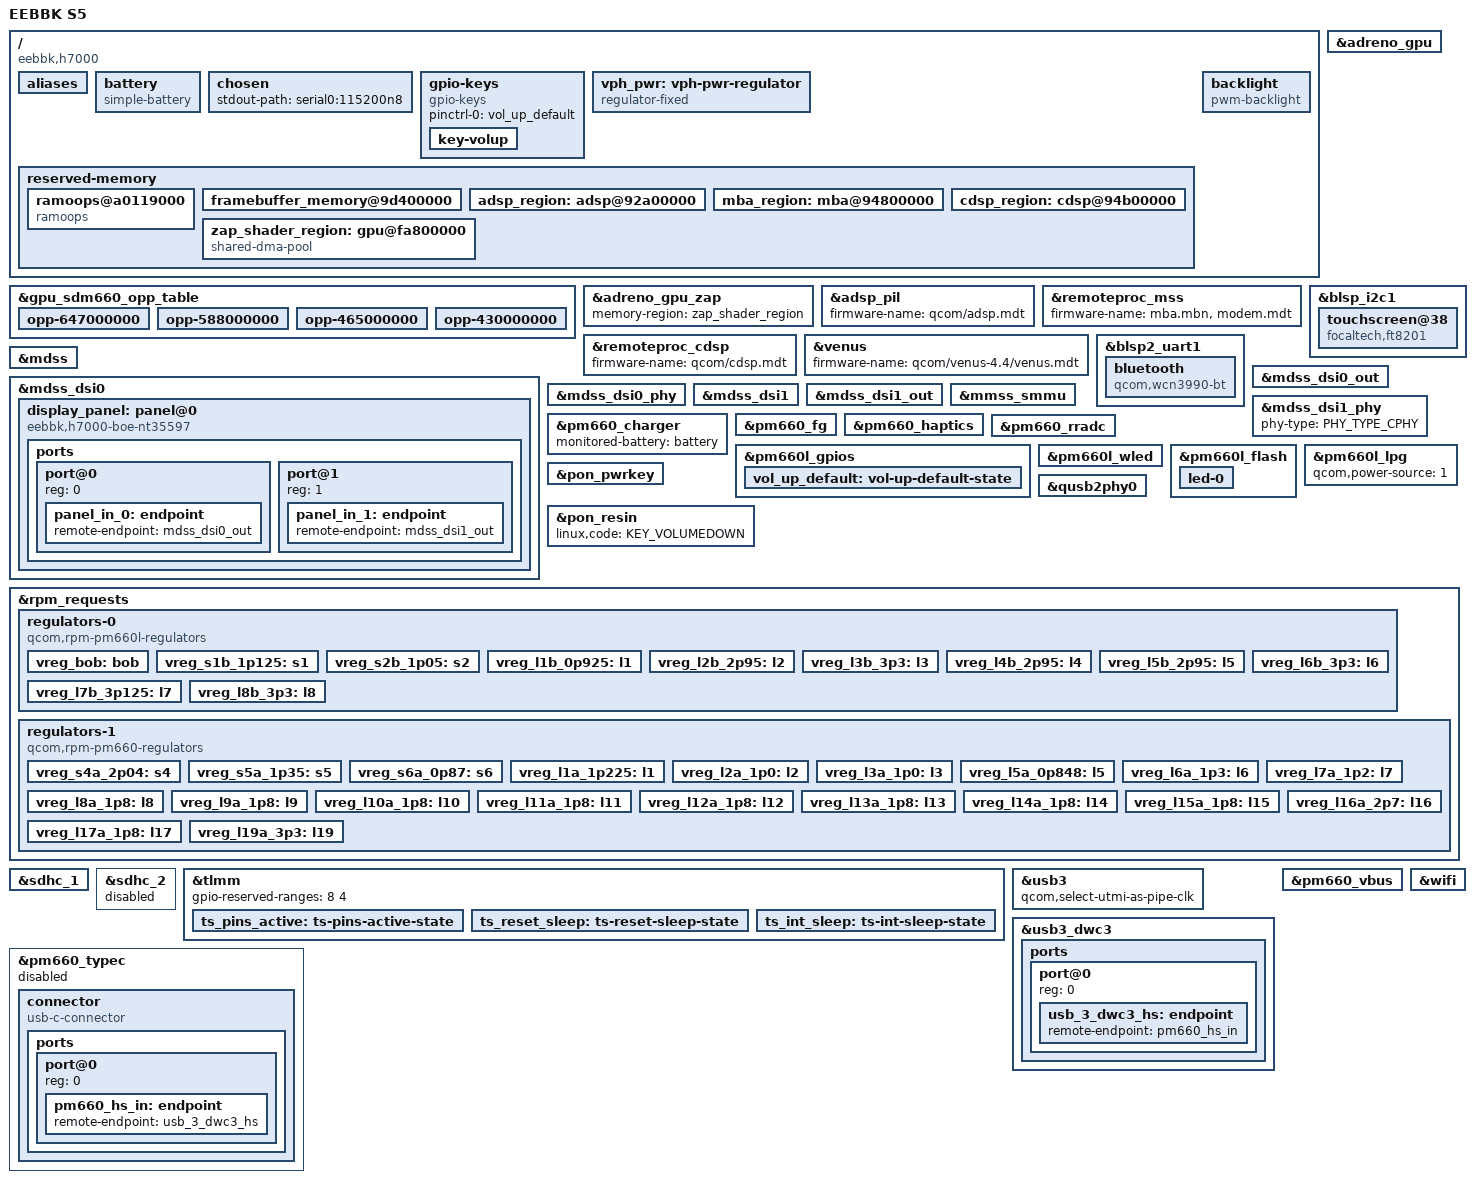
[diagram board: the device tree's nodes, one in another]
// SPDX-License-Identifier: BSD-3-Clause
/*
* Copyright (c) 2025-2026, XiKoTaSu <3329989998@qq.com>
* Copyright (c) 2026, thka <thka2020@qq.com>
*/

/dts-v1/;

#include "sdm660.dtsi"
#include "pm660.dtsi"
#include "pm660l.dtsi"
#include <dt-bindings/gpio/gpio.h>
#include <dt-bindings/input/input.h>
#include <dt-bindings/input/gpio-keys.h>
#include <dt-bindings/leds/common.h>
#include <dt-bindings/pinctrl/qcom,pmic-gpio.h>
#include <dt-bindings/sound/qcom,q6afe.h>
#include <dt-bindings/sound/qcom,q6asm.h>
#include <dt-bindings/phy/phy.h>

/delete-node/ &adsp_region;
/delete-node/ &cdsp_region;
/delete-node/ &mba_region;
/delete-node/ &zap_shader_region;

/ {
	model = "EEBBK S5";
	compatible = "eebbk,h7000", "qcom,sda660";
	chassis-type = "tablet";

	aliases {
		serial0 = &blsp1_uart2; /* Debug UART */
		serial1 = &blsp2_uart1; /* Bluetooth UART */
	};

	battery: battery {
		compatible = "simple-battery";

		charge-full-design-microamp-hours = <6665000>;
		voltage-min-design-microvolt = <3400000>;
		voltage-max-design-microvolt = <4408000>;
	};

	chosen {
		#address-cells = <2>;
		#size-cells = <2>;
		ranges;

		stdout-path = "serial0:115200n8";

		// framebuffer0: framebuffer@9d400000 {
		// 	compatible = "simple-framebuffer";
		// 	reg = <0 0x9d400000 0x0 0x2400000>;
		// 	width = <1600>;
		// 	height = <2176>;
		// 	stride = <(1600 * 4)>;
		// 	format = "a8r8g8b8";
		// };
	};

	gpio-keys {
		compatible = "gpio-keys";

		pinctrl-0 = <&vol_up_default>;
		pinctrl-names = "default";

		key-volup {
			label = "Volume Up";
			gpios = <&pm660l_gpios 7 GPIO_ACTIVE_LOW>;
			linux,code = <KEY_VOLUMEUP>;
			debounce-interval = <15>;
		};
	};

	vph_pwr: vph-pwr-regulator {
		compatible = "regulator-fixed";
		regulator-name = "vph_pwr";
		regulator-min-microvolt = <3700000>;
		regulator-max-microvolt = <3700000>;

		regulator-always-on;
		regulator-boot-on;
	};

	reserved-memory {
		#address-cells = <2>;
		#size-cells = <2>;
		ranges;

		ramoops@a0119000 {
			compatible = "ramoops";
			reg = <0x0 0xa0119000 0x0 0xe0000>;
			console-size = <0x10000>;
			record-size = <0x1000>;
			ftrace-size = <0x1000>;
			pmsg-size = <0x10000>;
		};

		framebuffer_memory@9d400000 {
			reg = <0x0 0x9d400000 0x0 0x2400000>;
			no-map;
		};
		
		adsp_region: adsp@92a00000 {
			reg = <0x0 0x92a00000 0x0 0x1e00000>;
			no-map;
		};

		mba_region: mba@94800000 {
			reg = <0x0 0x94800000 0x0 0x200000>;
			no-map;
		};

		cdsp_region: cdsp@94b00000 {
			reg = <0x00 0x94b00000 0x00 0x600000>;
			no-map;
		};
		
		zap_shader_region: gpu@fa800000 {
			compatible = "shared-dma-pool";
			reg = <0x0 0xfe700000 0x0 0x2000>;
			no-map;
		};
	};

	backlight: backlight {
		compatible = "pwm-backlight";
		pwms = <&pm660l_lpg 3 65536>;

		brightness-levels = <0 255>;
		num-interpolated-steps = <255>;
		default-brightness-level = <100>;
	};

};

&gpu_sdm660_opp_table {
		/* bins 157,146,135 -> bits 6,5,4 */
		opp-647000000 {
			opp-hz = /bits/ 64 <647000000>;
			opp-level = <RPM_SMD_LEVEL_NOM_PLUS>;
			opp-peak-kBps = <4068000>;
			opp-supported-hw = <0xff>;
		};

		/* bins 157,146,135 -> bits 6,5,4 */
		opp-588000000 {
			opp-hz = /bits/ 64 <588000000>;
			opp-level = <RPM_SMD_LEVEL_NOM>;
			opp-peak-kBps = <3072000>;
			opp-supported-hw = <0xff>;
		};

		/* bins 157,146,135,122 -> bits 6,5,4,3 */
		opp-465000000 {
			opp-hz = /bits/ 64 <465000000>;
			opp-level = <RPM_SMD_LEVEL_SVS_PLUS>;
			opp-peak-kBps = <2724000>;
			opp-supported-hw = <0xff>;
		};

		/* this one is for SDM636 with bin 90, bit 2 */
		opp-430000000 {
			opp-hz = /bits/ 64 <430000000>;
			opp-level = <RPM_SMD_LEVEL_SVS_PLUS>;
			opp-peak-kBps = <2724000>;
			opp-supported-hw = <0xff>;
		};
};

&adreno_gpu {
	status = "okay";
};

&adreno_gpu_zap {
	// firmware-name = "a512_zap.mdt"; /*If load it,device will reboot.*/
	memory-region = <&zap_shader_region>;
};

&adsp_pil {
	firmware-name = "qcom/adsp.mdt";
};

&remoteproc_mss {
	firmware-name = "mba.mbn", "modem.mdt";
	status = "okay";
};

&remoteproc_cdsp {
	firmware-name = "qcom/cdsp.mdt";
	status = "okay";
};

&venus {
	firmware-name = "qcom/venus-4.4/venus.mdt";
	// status = "okay"; /* If load it,device will reboot. */
};

&blsp_i2c1 {
	status = "okay";

	touchscreen@38 {
		compatible = "focaltech,ft8201";
		reg = <0x38>;
		interrupts-extended = <&tlmm 67 IRQ_TYPE_EDGE_FALLING>;
		reset-gpios = <&tlmm 66 GPIO_ACTIVE_LOW>;
		iovcc-supply = <&vreg_l11a_1p8>;

		pinctrl-0 = <&ts_pins_active>;
		pinctrl-1 = <&ts_int_sleep &ts_reset_sleep>;
		pinctrl-names = "default", "sleep";

		touchscreen-size-x = <1600>;
		touchscreen-size-y = <2176>;
	};
};

&blsp2_uart1 {
	status = "okay";

	bluetooth {
		compatible = "qcom,wcn3990-bt";
		vddxo-supply = <&vreg_l9a_1p8>;
		vddrf-supply = <&vreg_l6a_1p3>;
		vddch0-supply = <&vreg_l19a_3p3>;
		vddio-supply = <&vreg_l13a_1p8>;
		max-speed = <3200000>;
	};
};

&mdss {
	status = "okay";
};

&mdss_dsi0 {
	vdd-supply = <&vreg_l1b_0p925>;
	vdda-supply = <&vreg_l1a_1p225>;
	qcom,dual-dsi-mode;
	qcom,sync-dual-dsi;
	qcom,master-dsi;
	status = "okay";

	#address-cells = <0x01>;
	#size-cells = <0x00>;

	display_panel: panel@0 {
		compatible = "eebbk,h7000-boe-nt35597", "novatek,nt35597";
		reg = <0>;
		vddio-supply = <&vreg_l11a_1p8>;
		backlight = <&backlight>; /* Using pwm backlight */

		ports {
			#address-cells = <1>;
			#size-cells = <0>;

			port@0 {
				reg = <0>;

				panel_in_0: endpoint {
					remote-endpoint = <&mdss_dsi0_out>;
				};
			};

			port@1{
				reg = <1>;

				panel_in_1: endpoint {
					remote-endpoint = <&mdss_dsi1_out>;
				};
			};

		};
	};
};

&mdss_dsi0_out {
	data-lanes = <0 1 2 3>;
	remote-endpoint = <&panel_in_0>;
};

&mdss_dsi0_phy {
	vcca-supply = <&vreg_l1b_0p925>;
	phy-type = <PHY_TYPE_CPHY>;
	status = "okay";
};

&mdss_dsi1 {
	status = "okay";
};

&mdss_dsi1_out {
	data-lanes = <0 1 2 3>;
	remote-endpoint = <&panel_in_1>;
};

&mdss_dsi1_phy {
	phy-type = <PHY_TYPE_CPHY>;
	status = "okay";
};

&mmss_smmu {
	status = "okay";
};

&pm660_charger {
	monitored-battery = <&battery>;

	status = "okay";
};

&pm660_fg {
	monitored-battery = <&battery>;
	power-supplies = <&pm660_charger>;

	status = "okay";
};

&pm660_haptics {
	status = "okay";
};

&pm660_rradc {
	status = "okay";
};

&pm660l_gpios {
	vol_up_default: vol-up-default-state {
		pins = "gpio7";
		function = PMIC_GPIO_FUNC_NORMAL;
		bias-pull-up;
		input-enable;
		qcom,drive-strength = <PMIC_GPIO_STRENGTH_NO>;
	};
};
&pm660l_wled {
	qcom,switching-freq = <800>;
	qcom,current-limit-microamp = <20000>;
	qcom,num-strings = <2>;

	status = "okay";
};

&pm660l_flash {
	status = "okay";

	led-0 {
		function = LED_FUNCTION_FLASH;
		color = <LED_COLOR_ID_WHITE>;
		led-sources = <1>;
		led-max-microamp = <500000>;
		flash-max-microamp = <1500000>;
		flash-max-timeout-us = <1280000>;
	};
};

&pm660l_lpg {
	#address-cells = <1>;
	#size-cells = <0>;
	qcom,power-source = <1>;

	#pwm-cells = <2>;
	status = "okay";
};

&pon_pwrkey {
	status = "okay";
};

&pon_resin {
	linux,code = <KEY_VOLUMEDOWN>;

	status = "okay";
};

&qusb2phy0 {
	vdd-supply = <&vreg_l1b_0p925>;
	vdda-pll-supply = <&vreg_l10a_1p8>;
	vdda-phy-dpdm-supply = <&vreg_l7b_3p125>;

	status = "okay";
};

&rpm_requests {
	regulators-0 {
		compatible = "qcom,rpm-pm660l-regulators";

		vdd_s1-supply = <&vph_pwr>;
		vdd_s2-supply = <&vph_pwr>;
		vdd_s3_s4-supply = <&vph_pwr>;
		vdd_s5-supply = <&vph_pwr>;
		vdd_s6-supply = <&vph_pwr>;

		vdd_l1_l9_l10-supply = <&vreg_s2b_1p05>;
		vdd_l2-supply = <&vreg_bob>;
		vdd_l3_l5_l7_l8-supply = <&vreg_bob>;
		vdd_l4_l6-supply = <&vreg_bob>;
		vdd_bob-supply = <&vph_pwr>;

		vreg_bob: bob {
			regulator-min-microvolt = <3300000>;
			regulator-max-microvolt = <3600000>;
			regulator-enable-ramp-delay = <500>;
		};

		vreg_s1b_1p125: s1 {
			regulator-min-microvolt = <1125000>;
			regulator-max-microvolt = <1125000>;
			regulator-enable-ramp-delay = <200>;
		};

		vreg_s2b_1p05: s2 {
			regulator-min-microvolt = <1050000>;
			regulator-max-microvolt = <1050000>;
			regulator-enable-ramp-delay = <200>;
		};

		/* LDOs */
		vreg_l1b_0p925: l1 {
			regulator-min-microvolt = <800000>;
			regulator-max-microvolt = <925000>;
			regulator-enable-ramp-delay = <250>;
			regulator-allow-set-load;
		};

		/* SDHCI 3.3V signal doesn't seem to be supported. */
		vreg_l2b_2p95: l2 {
			regulator-min-microvolt = <1648000>;
			regulator-max-microvolt = <3100000>;
			regulator-enable-ramp-delay = <250>;
			regulator-allow-set-load;
		};

		vreg_l3b_3p3: l3 {
			regulator-min-microvolt = <1710000>;
			regulator-max-microvolt = <3600000>;
			regulator-enable-ramp-delay = <250>;
			regulator-allow-set-load;
			regulator-always-on;
		};

		vreg_l4b_2p95: l4 {
			regulator-min-microvolt = <1700000>;
			regulator-max-microvolt = <2950000>;
			regulator-enable-ramp-delay = <250>;

			regulator-min-microamp = <200>;
			regulator-max-microamp = <600000>;
			regulator-system-load = <570000>;
			regulator-allow-set-load;
		};

		/*
		 * Downstream specifies a range of 1721-3600mV,
		 * but the only assigned consumers are SDHCI2 VMMC
		 * and Coresight QPDI that both request pinned 2.95V.
		 * Tighten the range to 1.8-3.328 (closest to 3.3) to
		 * make the mmc driver happy.
		 */
		vreg_l5b_2p95: l5 {
			regulator-min-microvolt = <1800000>;
			regulator-max-microvolt = <3328000>;
			regulator-enable-ramp-delay = <250>;
			regulator-allow-set-load;
			regulator-system-load = <800000>;
		};

		vreg_l6b_3p3: l6 {
			regulator-min-microvolt = <1704000>;
			regulator-max-microvolt = <3312000>;
			regulator-enable-ramp-delay = <250>;
			regulator-ramp-delay = <0>;
		};


		vreg_l7b_3p125: l7 {
			regulator-min-microvolt = <2700000>;
			regulator-max-microvolt = <3125000>;
			regulator-enable-ramp-delay = <250>;
		};

		vreg_l8b_3p3: l8 {
			regulator-min-microvolt = <3200000>;
			regulator-max-microvolt = <3400000>;
			regulator-enable-ramp-delay = <250>;
		};
	};

	regulators-1 {
		compatible = "qcom,rpm-pm660-regulators";

		vdd_s1-supply = <&vph_pwr>;
		vdd_s2-supply = <&vph_pwr>;
		vdd_s3-supply = <&vph_pwr>;
		vdd_s4-supply = <&vph_pwr>;
		vdd_s5-supply = <&vph_pwr>;
		vdd_s6-supply = <&vph_pwr>;

		vdd_l1_l6_l7-supply = <&vreg_s5a_1p35>;
		vdd_l2_l3-supply = <&vreg_s2b_1p05>;
		vdd_l5-supply = <&vreg_s2b_1p05>;
		vdd_l8_l9_l10_l11_l12_l13_l14-supply = <&vreg_s4a_2p04>;
		vdd_l15_l16_l17_l18_l19-supply = <&vreg_bob>;

		/*
		 * S1A (FTAPC0), S2A (FTAPC1), S3A (HFAPC1) are managed
		 * by the Core Power Reduction hardened (CPRh) and the
		 * Operating State Manager (OSM) HW automatically.
		 */

		vreg_s4a_2p04: s4 {
			regulator-min-microvolt = <1805000>;
			regulator-max-microvolt = <2040000>;
			regulator-enable-ramp-delay = <200>;
			regulator-always-on;
		};

		vreg_s5a_1p35: s5 {
			regulator-min-microvolt = <1224000>;
			regulator-max-microvolt = <1350000>;
			regulator-enable-ramp-delay = <200>;
		};

		vreg_s6a_0p87: s6 {
			regulator-min-microvolt = <504000>;
			regulator-max-microvolt = <992000>;
			regulator-enable-ramp-delay = <150>;
		};

		/* LDOs */
		vreg_l1a_1p225: l1 {
			regulator-min-microvolt = <1150000>;
			regulator-max-microvolt = <1250000>;
			regulator-enable-ramp-delay = <250>;
			regulator-allow-set-load;
		};

		vreg_l2a_1p0: l2 {
			regulator-min-microvolt = <950000>;
			regulator-max-microvolt = <1010000>;
			regulator-enable-ramp-delay = <250>;
		};

		vreg_l3a_1p0: l3 {
			regulator-min-microvolt = <950000>;
			regulator-max-microvolt = <1010000>;
			regulator-enable-ramp-delay = <250>;
		};

		vreg_l5a_0p848: l5 {
			regulator-min-microvolt = <525000>;
			regulator-max-microvolt = <950000>;
			regulator-enable-ramp-delay = <250>;
		};

		vreg_l6a_1p3: l6 {
			regulator-min-microvolt = <1200000>;
			regulator-max-microvolt = <1370000>;
			regulator-allow-set-load;
			regulator-enable-ramp-delay = <250>;
		};

		vreg_l7a_1p2: l7 {
			regulator-min-microvolt = <1200000>;
			regulator-max-microvolt = <1200000>;
			regulator-enable-ramp-delay = <250>;
		};

		vreg_l8a_1p8: l8 {
			regulator-min-microvolt = <1750000>;
			regulator-max-microvolt = <1900000>;
			regulator-enable-ramp-delay = <250>;
			regulator-system-load = <325000>;
			regulator-allow-set-load;
		};

		vreg_l9a_1p8: l9 {
			regulator-min-microvolt = <1750000>;
			regulator-max-microvolt = <1900000>;
			regulator-enable-ramp-delay = <250>;
			regulator-allow-set-load;
		};

		vreg_l10a_1p8: l10 {
			regulator-min-microvolt = <1780000>;
			regulator-max-microvolt = <1950000>;
			regulator-enable-ramp-delay = <250>;
			regulator-allow-set-load;
			regulator-system-load = <14000>;
		};

		vreg_l11a_1p8: l11 {
			regulator-min-microvolt = <1780000>;
			regulator-max-microvolt = <1950000>;
			regulator-enable-ramp-delay = <250>;
		};

		vreg_l12a_1p8: l12 {
			regulator-min-microvolt = <1780000>;
			regulator-max-microvolt = <1950000>;
			regulator-enable-ramp-delay = <250>;
		};

		/* This gives power to the LPDDR4: never turn it off! */
		vreg_l13a_1p8: l13 {
			regulator-min-microvolt = <1780000>;
			regulator-max-microvolt = <1950000>;
			regulator-enable-ramp-delay = <250>;
			regulator-boot-on;
			regulator-always-on;
		};

		vreg_l14a_1p8: l14 {
			regulator-min-microvolt = <1710000>;
			regulator-max-microvolt = <1900000>;
			regulator-enable-ramp-delay = <250>;
		};

		vreg_l15a_1p8: l15 {
			regulator-min-microvolt = <1650000>;
			regulator-max-microvolt = <2950000>;
			regulator-enable-ramp-delay = <250>;
		};

		vreg_l16a_2p7: l16 {
			regulator-min-microvolt = <2800000>;
			regulator-max-microvolt = <2800000>;
			regulator-enable-ramp-delay = <250>;
			regulator-always-on;
		};

		vreg_l17a_1p8: l17 {
			regulator-min-microvolt = <1650000>;
			regulator-max-microvolt = <2950000>;
			regulator-enable-ramp-delay = <250>;
		};

		vreg_l19a_3p3: l19 {
			regulator-min-microvolt = <3200000>;
			regulator-max-microvolt = <3400000>;
			regulator-enable-ramp-delay = <250>;
			regulator-allow-set-load;
		};
	};
};

&sdhc_1 {
	supports-cqe;

	mmc-hs200-1_8v;
	mmc-hs400-1_8v;
	mmc-hs400-enhanced-strobe;

	vmmc-supply = <&vreg_l4b_2p95>;
	vqmmc-supply = <&vreg_l8a_1p8>;

	status = "okay";
};

&sdhc_2 {
	cd-gpios = <&tlmm 54 GPIO_ACTIVE_LOW>;
	vmmc-supply = <&vreg_l5b_2p95>;
	vqmmc-supply = <&vreg_l2b_2p95>;

	status = "disabled";/* H7000 doesn't have any SD card */
};

&tlmm {
	gpio-reserved-ranges = <8 4>;

	ts_pins_active: ts-pins-active-state {
		pins = "gpio66", "gpio67";
		function = "gpio";
		drive-strength = <10>;
		bias-pull-up;
	};

	ts_reset_sleep: ts-reset-sleep-state {
		pins = "gpio66";
		function = "gpio";
		drive-strength = <2>;
		bias-pull-down;
	};

	ts_int_sleep: ts-int-sleep-state {
		pins = "gpio67";
		function = "gpio";
		drive-strength = <2>;
		bias-disable;
	};
};

&usb3 {
	qcom,select-utmi-as-pipe-clk;
	status = "okay";
};

&usb3_dwc3 {
	maximum-speed = "high-speed";
	phys = <&qusb2phy0>;
	phy-names = "usb2-phy";
	usb-role-switch;
	dr_mode = "otg";

	ports {
		#address-cells = <1>;
		#size-cells = <0>;

		port@0 {
			reg = <0>;

			usb_3_dwc3_hs: endpoint { };
		};
	};
};

&pm660_vbus {
	status = "okay";
};

&pm660_typec {
	status = "disabled"; /* Why use it? It is micro usb. */

	connector {
		compatible = "usb-c-connector";

		ports {
			#address-cells = <1>;
			#size-cells = <0>;

			port@0 {
				reg = <0>;
				pm660_hs_in: endpoint {
					remote-endpoint = <&usb_3_dwc3_hs>;
				};
			};
		};
	};
};

&usb_3_dwc3_hs {
	remote-endpoint = <&pm660_hs_in>;
};

&wifi {
	vdd-0.8-cx-mx-supply = <&vreg_l5a_0p848>;
	vdd-1.8-xo-supply = <&vreg_l9a_1p8>;
	vdd-1.3-rfa-supply = <&vreg_l6a_1p3>;
	vdd-3.3-ch0-supply = <&vreg_l19a_3p3>;
	vdd-3.3-ch1-supply = <&vreg_l19a_3p3>;

	qcom,calibration-variant = "eebbk_h7000";
	status = "okay";
};
